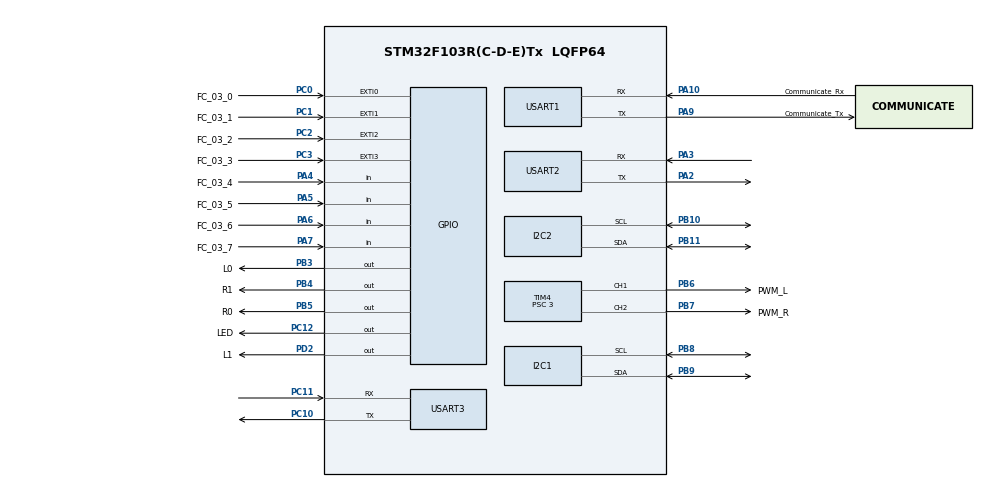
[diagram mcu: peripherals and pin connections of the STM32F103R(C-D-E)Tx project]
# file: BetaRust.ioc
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I2C1.I2C_Mode=I2C_Standard
Mcu.Family=STM32F1
Mcu.Name=STM32F103R(C-D-E)Tx
Mcu.Package=LQFP64
NVIC.EXTI0_IRQn=true\:0\:0\:false\:false\:true
NVIC.EXTI1_IRQn=true\:0\:0\:false\:false\:true
NVIC.EXTI2_IRQn=true\:0\:0\:false\:false\:true
NVIC.EXTI3_IRQn=true\:0\:0\:false\:false\:true
NVIC.PriorityGroup=NVIC_PRIORITYGROUP_4
NVIC.TIM2_IRQn=true\:0\:0\:false\:false\:true
NVIC.TIM3_IRQn=true\:0\:0\:false\:false\:true
NVIC.TIM4_IRQn=true\:0\:0\:false\:false\:true
NVIC.TIM5_IRQn=true\:0\:0\:false\:false\:true
NVIC.TIM6_IRQn=true\:0\:0\:false\:false\:true
NVIC.TIM7_IRQn=true\:0\:0\:false\:false\:true
PA10.GPIO_Label=Communicate_Rx
PA10.Mode=Asynchronous
PA10.Signal=USART1_RX
PA13.Mode=Serial_Wire
PA13.Signal=SYS_JTMS-SWDIO
PA14.Mode=Serial_Wire
PA14.Signal=SYS_JTCK-SWCLK
PA2.Mode=Asynchronous
PA2.Signal=USART2_TX
PA3.Mode=Asynchronous
PA3.Signal=USART2_RX
PA4.GPIO_Label=FC_03_4
PA4.Signal=GPIO_Input
PA5.GPIO_Label=FC_03_5
PA5.Signal=GPIO_Input
PA6.GPIO_Label=FC_03_6
PA6.Signal=GPIO_Input
PA7.GPIO_Label=FC_03_7
PA7.Signal=GPIO_Input
PA9.GPIO_Label=Communicate_Tx
PA9.Mode=Asynchronous
PA9.Signal=USART1_TX
PB10.Mode=I2C
PB10.Signal=I2C2_SCL
PB11.Mode=I2C
PB11.Signal=I2C2_SDA
PB3.GPIO_Label=L0
PB3.Signal=GPIO_Output
PB4.GPIO_Label=R1
PB4.Signal=GPIO_Output
PB5.GPIO_Label=R0
PB5.Signal=GPIO_Output
PB6.GPIO_Label=PWM_L
PB6.Signal=S_TIM4_CH1
PB7.GPIO_Label=PWM_R
PB7.Signal=S_TIM4_CH2
PB8.Mode=I2C
PB8.Signal=I2C1_SCL
PB9.Mode=I2C
PB9.Signal=I2C1_SDA
PC0.GPIO_Label=FC_03_0
PC0.GPIO_ModeDefaultEXTI=GPIO_MODE_IT_RISING
PC0.Signal=GPXTI0
PC1.GPIO_Label=FC_03_1
PC1.Signal=GPXTI1
PC10.Mode=Asynchronous
PC10.Signal=USART3_TX
PC11.Mode=Asynchronous
PC11.Signal=USART3_RX
PC12.GPIO_Label=LED
PC12.Signal=GPIO_Output
PC2.GPIO_Label=FC_03_2
PC2.Signal=GPXTI2
PC3.GPIO_Label=FC_03_3
PC3.Signal=GPXTI3
PD2.GPIO_Label=L1
PD2.Signal=GPIO_Output
ProjectManager.HeapSize=0x200
ProjectManager.StackSize=0x400
ProjectManager.TargetToolchain=MDK-ARM V5
RCC.AHBFreq_Value=8000000
RCC.APB1Freq_Value=8000000
RCC.APB1TimFreq_Value=8000000
RCC.APB2Freq_Value=8000000
RCC.APB2TimFreq_Value=8000000
RCC.HCLKFreq_Value=8000000
SH.S_TIM4_CH1.0=TIM4_CH1,PWM Generation1 CH1
SH.S_TIM4_CH2.0=TIM4_CH2,PWM Generation2 CH2
TIM1.Period=1999
TIM1.Prescaler=3
TIM2.Period=1999
TIM2.Prescaler=3
TIM3.Period=1999
TIM3.Prescaler=3
TIM4.Channel-PWM\ Generation2\ CH2=TIM_CHANNEL_2
TIM4.Period=1999
TIM4.Prescaler=3
TIM5.Period=1999
TIM5.Prescaler=3
TIM8.Period=1999
TIM8.Prescaler=3
VP_TIM1_VS_ClockSourceINT.Mode=Internal
VP_TIM2_VS_ClockSourceINT.Mode=Internal
VP_TIM3_VS_ClockSourceINT.Mode=Internal
VP_TIM4_VS_ClockSourceINT.Mode=Internal
VP_TIM5_VS_ClockSourceINT.Mode=Internal
VP_TIM6_VS_ClockSourceINT.Mode=Enable_Timer
VP_TIM7_VS_ClockSourceINT.Mode=Enable_Timer
VP_TIM8_VS_ClockSourceINT.Mode=Internal
board=BetaRust

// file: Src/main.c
/**
  ******************************************************************************
  * File Name          : main.c
  * Description        : Main program body
  ******************************************************************************
  *
  * COPYRIGHT(c) 2016 STMicroelectronics
  *
  * Redistribution and use in source and binary forms, with or without modification,
  * are permitted provided that the following conditions are met:
  *   1. Redistributions of source code must retain the above copyright notice,
  *      this list of conditions and the following disclaimer.
  *   2. Redistributions in binary form must reproduce the above copyright notice,
  *      this list of conditions and the following disclaimer in the documentation
  *      and/or other materials provided with the distribution.
  *   3. Neither the name of STMicroelectronics nor the names of its contributors
  *      may be used to endorse or promote products derived from this software
  *      without specific prior written permission.
  *
  * THIS SOFTWARE IS PROVIDED BY THE COPYRIGHT HOLDERS AND CONTRIBUTORS "AS IS"
  * AND ANY EXPRESS OR IMPLIED WARRANTIES, INCLUDING, BUT NOT LIMITED TO, THE
  * IMPLIED WARRANTIES OF MERCHANTABILITY AND FITNESS FOR A PARTICULAR PURPOSE ARE
  * DISCLAIMED. IN NO EVENT SHALL THE COPYRIGHT HOLDER OR CONTRIBUTORS BE LIABLE
  * FOR ANY DIRECT, INDIRECT, INCIDENTAL, SPECIAL, EXEMPLARY, OR CONSEQUENTIAL
  * DAMAGES (INCLUDING, BUT NOT LIMITED TO, PROCUREMENT OF SUBSTITUTE GOODS OR
  * SERVICES; LOSS OF USE, DATA, OR PROFITS; OR BUSINESS INTERRUPTION) HOWEVER
  * CAUSED AND ON ANY THEORY OF LIABILITY, WHETHER IN CONTRACT, STRICT LIABILITY,
  * OR TORT (INCLUDING NEGLIGENCE OR OTHERWISE) ARISING IN ANY WAY OUT OF THE USE
  * OF THIS SOFTWARE, EVEN IF ADVISED OF THE POSSIBILITY OF SUCH DAMAGE.
  *
  ******************************************************************************
  */
#include "stm32f1xx_hal.h"
#include "i2c.h"
#include "tim.h"
#include "usart.h"
#include "gpio.h"

/* USER CODE BEGIN Includes */
#include "user.h"
/* USER CODE END Includes */

/* USER CODE BEGIN PV */
/* Private variables ---------------------------------------------------------*/

/* USER CODE END PV */

void SystemClock_Config(void);
void Error_Handler(void);

/* USER CODE BEGIN PFP */
/* Private function prototypes -----------------------------------------------*/
void HAL_TIM_PeriodElapsedCallback(TIM_HandleTypeDef *htim);
void HAL_GPIO_EXTI_Callback(uint16_t GPIO_Pin);
/* USER CODE END PFP */

int main(void)
{

  /* MCU Configuration----------------------------------------------------------*/

  /* Reset of all peripherals, Initializes the Flash interface and the Systick. */
  HAL_Init();

  /* Configure the system clock */
  SystemClock_Config();

  /* Initialize all configured peripherals */
  MX_GPIO_Init();
  MX_TIM1_Init();
  MX_I2C1_Init();
  MX_I2C2_Init();
  MX_TIM2_Init();
  MX_TIM3_Init();
  MX_TIM4_Init();
  MX_TIM5_Init();
  MX_TIM8_Init();
  MX_USART1_UART_Init();
  MX_USART3_UART_Init();
  MX_TIM6_Init();
  MX_TIM7_Init();
  MX_USART2_UART_Init();
  /* USER CODE BEGIN 2 */
	HAL_TIM_PWM_Start(&htim4,TIM_CHANNEL_1);
	HAL_TIM_PWM_Start(&htim4,TIM_CHANNEL_2);
  /* USER CODE END 2 */
  /* Infinite loop */
  while (1)
  {
		//egs
		set_speed(127,127);
		HAL_Delay(2000);
		set_speed(0,127);
		HAL_Delay(2000);
		set_speed(-128,127);
		HAL_Delay(2000);
		set_speed(127,0);
		HAL_Delay(2000);
		set_speed(0,0);
		HAL_Delay(2000);
		set_speed(-128,0);
		HAL_Delay(2000);
		set_speed(127,-128);
		HAL_Delay(2000);
		set_speed(0,-128);
		HAL_Delay(2000);
		set_speed(-128,-128);
		HAL_Delay(2000);
  }

}

/** System Clock Configuration
*/
void SystemClock_Config(void)
{

  RCC_OscInitTypeDef RCC_OscInitStruct;
  RCC_ClkInitTypeDef RCC_ClkInitStruct;

  RCC_OscInitStruct.OscillatorType = RCC_OSCILLATORTYPE_HSI;
  RCC_OscInitStruct.HSIState = RCC_HSI_ON;
  RCC_OscInitStruct.HSICalibrationValue = 16;
  RCC_OscInitStruct.PLL.PLLState = RCC_PLL_NONE;
  if (HAL_RCC_OscConfig(&RCC_OscInitStruct) != HAL_OK)
  {
    Error_Handler();
  }

  RCC_ClkInitStruct.ClockType = RCC_CLOCKTYPE_HCLK|RCC_CLOCKTYPE_SYSCLK
                              |RCC_CLOCKTYPE_PCLK1|RCC_CLOCKTYPE_PCLK2;
  RCC_ClkInitStruct.SYSCLKSource = RCC_SYSCLKSOURCE_HSI;
  RCC_ClkInitStruct.AHBCLKDivider = RCC_SYSCLK_DIV1;
  RCC_ClkInitStruct.APB1CLKDivider = RCC_HCLK_DIV1;
  RCC_ClkInitStruct.APB2CLKDivider = RCC_HCLK_DIV1;
  if (HAL_RCC_ClockConfig(&RCC_ClkInitStruct, FLASH_LATENCY_0) != HAL_OK)
  {
    Error_Handler();
  }

  HAL_SYSTICK_Config(HAL_RCC_GetHCLKFreq()/1000);

  HAL_SYSTICK_CLKSourceConfig(SYSTICK_CLKSOURCE_HCLK);

  /* SysTick_IRQn interrupt configuration */
  HAL_NVIC_SetPriority(SysTick_IRQn, 0, 0);
}

/* USER CODE BEGIN 4 */
void HAL_TIM_PeriodElapsedCallback(TIM_HandleTypeDef *htim)
{

}
void HAL_GPIO_EXTI_Callback(uint16_t GPIO_Pin)
{
}
/* USER CODE END 4 */

void Error_Handler(void)
{
  while(1)
  {
  }
}

/************************ (C) COPYRIGHT STMicroelectronics *****END OF FILE****/
